# ESP32-H21 register map
Vendor: ESPRESSIF SYSTEMS (SHANGHAI) CO., LTD.; Series: ESP32 H-Series; File version: 1
CPU: RV32IMAC r0p0, little endian, no MPU, no FPU, 0 interrupt priority bits
Address unit: 32 bits
Registers are 32-bit, read-write, reset 0x0 unless marked. A register's access mark holds for its fields unless they carry their own. Offsets are from the block's base; [hi:lo] are bit positions; {n}, {i} and the like mark numbered series.

## DMA — DMA (Direct Memory Access) Controller
Base 0x60080000
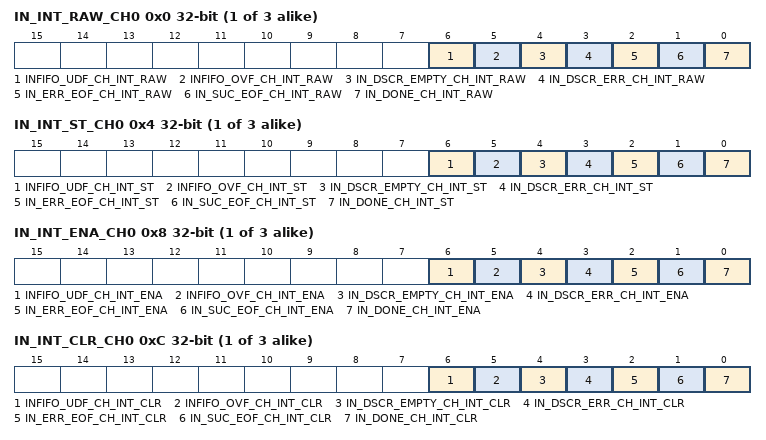
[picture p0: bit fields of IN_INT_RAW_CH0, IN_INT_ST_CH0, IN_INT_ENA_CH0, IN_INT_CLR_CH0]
{0x0+0x10*i} IN_INT_RAW_CH{i} (i=0..2) — Raw status interrupt of channel {i}
  [6] INFIFO_UDF_CH_INT_RAW — This raw interrupt bit turns to high level when level 1 fifo of Rx channel 0 is underflow.
  [5] INFIFO_OVF_CH_INT_RAW — This raw interrupt bit turns to high level when level 1 fifo of Rx channel 0 is overflow.
  [4] IN_DSCR_EMPTY_CH_INT_RAW — The raw interrupt bit turns to high level when Rx buffer pointed by inlink is full and receiving data is not completed but there is no more inlink for Rx channel 0.
  [3] IN_DSCR_ERR_CH_INT_RAW — The raw interrupt bit turns to high level when detecting inlink descriptor error including owner error and the second and third word error of inlink descriptor for Rx channel 0.
  [2] IN_ERR_EOF_CH_INT_RAW — The raw interrupt bit turns to high level when data error is detected only in the case that the peripheral is UHCI0 for Rx channel 0. For other peripherals this raw interrupt is reserved.
  [1] IN_SUC_EOF_CH_INT_RAW — The raw interrupt bit turns to high level when the last data pointed by one inlink descriptor has been received for Rx channel 0. For UHCI0 the raw interrupt bit turns to high level when the last data pointed by one inlink descriptor has been received and no data error is detected for Rx channel 0.
  [0] IN_DONE_CH_INT_RAW — The raw interrupt bit turns to high level when the last data pointed by one inlink descriptor has been received for Rx channel 0.
{0x4+0x10*i} IN_INT_ST_CH{i} (i=0..2) ro — Masked interrupt of channel {i}
  [6] INFIFO_UDF_CH_INT_ST — The raw interrupt status bit for the INFIFO_UDF_L1_CH_INT interrupt.
  [5] INFIFO_OVF_CH_INT_ST — The raw interrupt status bit for the INFIFO_OVF_L1_CH_INT interrupt.
  [4] IN_DSCR_EMPTY_CH_INT_ST — The raw interrupt status bit for the IN_DSCR_EMPTY_CH_INT interrupt.
  [3] IN_DSCR_ERR_CH_INT_ST — The raw interrupt status bit for the IN_DSCR_ERR_CH_INT interrupt.
  [2] IN_ERR_EOF_CH_INT_ST — The raw interrupt status bit for the IN_ERR_EOF_CH_INT interrupt.
  [1] IN_SUC_EOF_CH_INT_ST — The raw interrupt status bit for the IN_SUC_EOF_CH_INT interrupt.
  [0] IN_DONE_CH_INT_ST — The raw interrupt status bit for the IN_DONE_CH_INT interrupt.
{0x8+0x10*i} IN_INT_ENA_CH{i} (i=0..2) — Interrupt enable bits of channel {i}
  [6] INFIFO_UDF_CH_INT_ENA — The interrupt enable bit for the INFIFO_UDF_L1_CH_INT interrupt.
  [5] INFIFO_OVF_CH_INT_ENA — The interrupt enable bit for the INFIFO_OVF_L1_CH_INT interrupt.
  [4] IN_DSCR_EMPTY_CH_INT_ENA — The interrupt enable bit for the IN_DSCR_EMPTY_CH_INT interrupt.
  [3] IN_DSCR_ERR_CH_INT_ENA — The interrupt enable bit for the IN_DSCR_ERR_CH_INT interrupt.
  [2] IN_ERR_EOF_CH_INT_ENA — The interrupt enable bit for the IN_ERR_EOF_CH_INT interrupt.
  [1] IN_SUC_EOF_CH_INT_ENA — The interrupt enable bit for the IN_SUC_EOF_CH_INT interrupt.
  [0] IN_DONE_CH_INT_ENA — The interrupt enable bit for the IN_DONE_CH_INT interrupt.
{0xC+0x10*i} IN_INT_CLR_CH{i} (i=0..2) wo — Interrupt clear bits of channel {i}
  [6] INFIFO_UDF_CH_INT_CLR — Set this bit to clear the INFIFO_UDF_L1_CH_INT interrupt.
  [5] INFIFO_OVF_CH_INT_CLR — Set this bit to clear the INFIFO_OVF_L1_CH_INT interrupt.
  [4] IN_DSCR_EMPTY_CH_INT_CLR — Set this bit to clear the IN_DSCR_EMPTY_CH_INT interrupt.
  [3] IN_DSCR_ERR_CH_INT_CLR — Set this bit to clear the IN_DSCR_ERR_CH_INT interrupt.
  [2] IN_ERR_EOF_CH_INT_CLR — Set this bit to clear the IN_ERR_EOF_CH_INT interrupt.
  [1] IN_SUC_EOF_CH_INT_CLR — Set this bit to clear the IN_SUC_EOF_CH_INT interrupt.
  [0] IN_DONE_CH_INT_CLR — Set this bit to clear the IN_DONE_CH_INT interrupt.
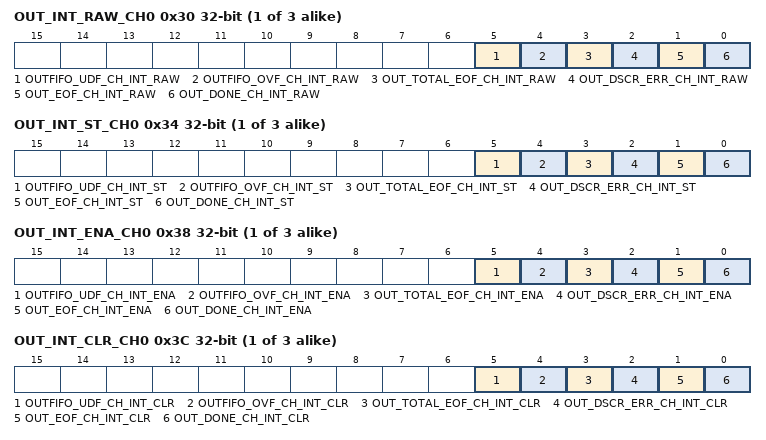
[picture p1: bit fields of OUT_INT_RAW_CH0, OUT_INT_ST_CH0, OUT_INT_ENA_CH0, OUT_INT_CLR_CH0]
{0x30+0x10*i} OUT_INT_RAW_CH{i} (i=0..2) — Raw status interrupt of channel {i}
  [5] OUTFIFO_UDF_CH_INT_RAW — This raw interrupt bit turns to high level when level 1 fifo of Tx channel 0 is underflow.
  [4] OUTFIFO_OVF_CH_INT_RAW — This raw interrupt bit turns to high level when level 1 fifo of Tx channel 0 is overflow.
  [3] OUT_TOTAL_EOF_CH_INT_RAW — The raw interrupt bit turns to high level when data corresponding a outlink (includes one link descriptor or few link descriptors) is transmitted out for Tx channel 0.
  [2] OUT_DSCR_ERR_CH_INT_RAW — The raw interrupt bit turns to high level when detecting outlink descriptor error including owner error and the second and third word error of outlink descriptor for Tx channel 0.
  [1] OUT_EOF_CH_INT_RAW — The raw interrupt bit turns to high level when the last data pointed by one outlink descriptor has been read from memory for Tx channel 0.
  [0] OUT_DONE_CH_INT_RAW — The raw interrupt bit turns to high level when the last data pointed by one outlink descriptor has been transmitted to peripherals for Tx channel 0.
{0x34+0x10*i} OUT_INT_ST_CH{i} (i=0..2) ro — Masked interrupt of channel {i}
  [5] OUTFIFO_UDF_CH_INT_ST — The raw interrupt status bit for the OUTFIFO_UDF_L1_CH_INT interrupt.
  [4] OUTFIFO_OVF_CH_INT_ST — The raw interrupt status bit for the OUTFIFO_OVF_L1_CH_INT interrupt.
  [3] OUT_TOTAL_EOF_CH_INT_ST — The raw interrupt status bit for the OUT_TOTAL_EOF_CH_INT interrupt.
  [2] OUT_DSCR_ERR_CH_INT_ST — The raw interrupt status bit for the OUT_DSCR_ERR_CH_INT interrupt.
  [1] OUT_EOF_CH_INT_ST — The raw interrupt status bit for the OUT_EOF_CH_INT interrupt.
  [0] OUT_DONE_CH_INT_ST — The raw interrupt status bit for the OUT_DONE_CH_INT interrupt.
{0x38+0x10*i} OUT_INT_ENA_CH{i} (i=0..2) — Interrupt enable bits of channel {i}
  [5] OUTFIFO_UDF_CH_INT_ENA — The interrupt enable bit for the OUTFIFO_UDF_L1_CH_INT interrupt.
  [4] OUTFIFO_OVF_CH_INT_ENA — The interrupt enable bit for the OUTFIFO_OVF_L1_CH_INT interrupt.
  [3] OUT_TOTAL_EOF_CH_INT_ENA — The interrupt enable bit for the OUT_TOTAL_EOF_CH_INT interrupt.
  [2] OUT_DSCR_ERR_CH_INT_ENA — The interrupt enable bit for the OUT_DSCR_ERR_CH_INT interrupt.
  [1] OUT_EOF_CH_INT_ENA — The interrupt enable bit for the OUT_EOF_CH_INT interrupt.
  [0] OUT_DONE_CH_INT_ENA — The interrupt enable bit for the OUT_DONE_CH_INT interrupt.
{0x3C+0x10*i} OUT_INT_CLR_CH{i} (i=0..2) wo — Interrupt clear bits of channel {i}
  [5] OUTFIFO_UDF_CH_INT_CLR — Set this bit to clear the OUTFIFO_UDF_L1_CH_INT interrupt.
  [4] OUTFIFO_OVF_CH_INT_CLR — Set this bit to clear the OUTFIFO_OVF_L1_CH_INT interrupt.
  [3] OUT_TOTAL_EOF_CH_INT_CLR — Set this bit to clear the OUT_TOTAL_EOF_CH_INT interrupt.
  [2] OUT_DSCR_ERR_CH_INT_CLR — Set this bit to clear the OUT_DSCR_ERR_CH_INT interrupt.
  [1] OUT_EOF_CH_INT_CLR — Set this bit to clear the OUT_EOF_CH_INT interrupt.
  [0] OUT_DONE_CH_INT_CLR — Set this bit to clear the OUT_DONE_CH_INT interrupt.
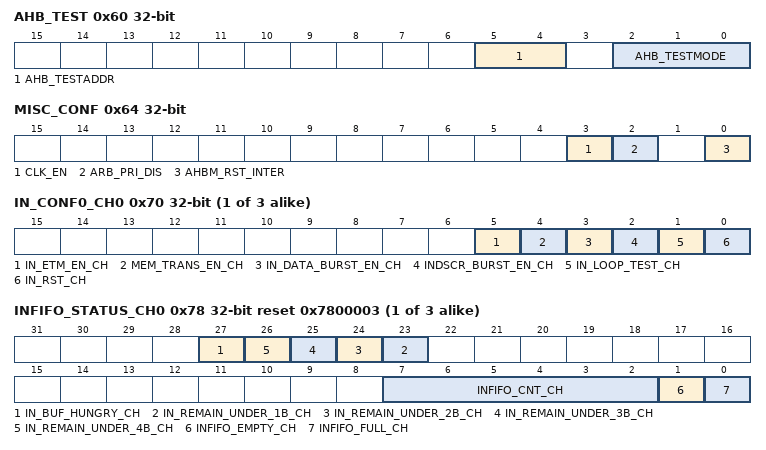
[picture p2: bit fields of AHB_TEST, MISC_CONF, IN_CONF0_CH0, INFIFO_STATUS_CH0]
0x60 AHB_TEST — reserved
  [5:4] AHB_TESTADDR — reserved
  [2:0] AHB_TESTMODE — reserved
0x64 MISC_CONF — MISC register
  [3] CLK_EN — 1'h1: Force clock on for register. 1'h0: Support clock only when application writes registers.
  [2] ARB_PRI_DIS — Set this bit to disable priority arbitration function.
  [0] AHBM_RST_INTER — Set this bit then clear this bit to reset the internal ahb FSM.
0x68 DATE reset 0x2202250 — Version control register
  [31:0] DATE — register version.
{0x70+0xC0*i} IN_CONF0_CH{i} (i=0..2) — Configure 0 register of Rx channel {i}
  [5] IN_ETM_EN_CH — Set this bit to 1 to enable etm control mode, dma Rx channel 0 is triggered by etm task.
  [4] MEM_TRANS_EN_CH — Set this bit 1 to enable automatic transmitting data from memory to memory via DMA.
  [3] IN_DATA_BURST_EN_CH — Set this bit to 1 to enable INCR burst transfer for Rx channel 0 receiving data when accessing internal SRAM.
  [2] INDSCR_BURST_EN_CH — Set this bit to 1 to enable INCR burst transfer for Rx channel 0 reading link descriptor when accessing internal SRAM.
  [1] IN_LOOP_TEST_CH — reserved
  [0] IN_RST_CH — This bit is used to reset DMA channel 0 Rx FSM and Rx FIFO pointer.
{0x74+0xC0*i} IN_CONF1_CH{i} (i=0..2) — Configure 1 register of Rx channel {i}
  [12] IN_CHECK_OWNER_CH — Set this bit to enable checking the owner attribute of the link descriptor.
{0x78+0xC0*i} INFIFO_STATUS_CH{i} (i=0..2) ro reset 0x7800003 — Receive FIFO status of Rx channel {i}
  [27] IN_BUF_HUNGRY_CH — reserved
  [n+22] IN_REMAIN_UNDER_{n}B_CH (n=1..4) — reserved
  [7:2] INFIFO_CNT_CH — The register stores the byte number of the data in L1 Rx FIFO for Rx channel 0.
  [1] INFIFO_EMPTY_CH — L1 Rx FIFO empty signal for Rx channel 0.
  [0] INFIFO_FULL_CH — L1 Rx FIFO full signal for Rx channel 0.
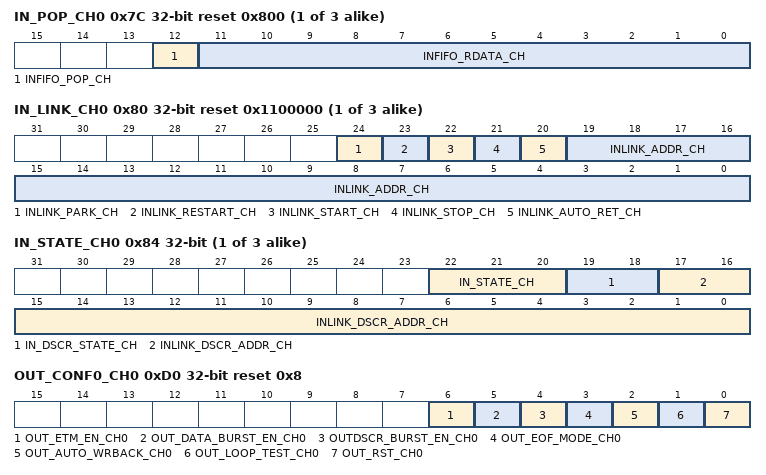
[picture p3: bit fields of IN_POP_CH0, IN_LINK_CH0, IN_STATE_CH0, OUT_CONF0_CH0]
{0x7C+0xC0*i} IN_POP_CH{i} (i=0..2) access per field reset 0x800 — Pop control register of Rx channel {i}
  [12] INFIFO_POP_CH wo — Set this bit to pop data from DMA FIFO.
  [11:0] INFIFO_RDATA_CH ro — This register stores the data popping from DMA FIFO.
{0x80+0xC0*i} IN_LINK_CH{i} (i=0..2) access per field reset 0x1100000 — Link descriptor configure and control register of Rx channel {i}
  [24] INLINK_PARK_CH ro — 1: the inlink descriptor's FSM is in idle state. 0: the inlink descriptor's FSM is working.
  [23] INLINK_RESTART_CH wo — Set this bit to mount a new inlink descriptor.
  [22] INLINK_START_CH wo — Set this bit to start dealing with the inlink descriptors.
  [21] INLINK_STOP_CH wo — Set this bit to stop dealing with the inlink descriptors.
  [20] INLINK_AUTO_RET_CH rw — Set this bit to return to current inlink descriptor's address when there are some errors in current receiving data.
  [19:0] INLINK_ADDR_CH rw — This register stores the 20 least significant bits of the first inlink descriptor's address.
{0x84+0xC0*i} IN_STATE_CH{i} (i=0..2) ro — Receive status of Rx channel {i}
  [22:20] IN_STATE_CH — reserved
  [19:18] IN_DSCR_STATE_CH — reserved
  [17:0] INLINK_DSCR_ADDR_CH — This register stores the current inlink descriptor's address.
{0x88+0xC0*i} IN_SUC_EOF_DES_ADDR_CH{i} (i=0..2) ro — Inlink descriptor address when EOF occurs of Rx channel {i}
  [31:0] IN_SUC_EOF_DES_ADDR_CH — This register stores the address of the inlink descriptor when the EOF bit in this descriptor is 1.
{0x8C+0xC0*i} IN_ERR_EOF_DES_ADDR_CH{i} (i=0..2) ro — Inlink descriptor address when errors occur of Rx channel {i}
  [31:0] IN_ERR_EOF_DES_ADDR_CH — This register stores the address of the inlink descriptor when there are some errors in current receiving data. Only used when peripheral is UHCI0.
{0x90+0xC0*i} IN_DSCR_CH{i} (i=0..2) ro — Current inlink descriptor address of Rx channel {i}
  [31:0] INLINK_DSCR_CH — The address of the current inlink descriptor x.
{0x94+0xC0*i} IN_DSCR_BF0_CH{i} (i=0..2) ro — The last inlink descriptor address of Rx channel {i}
  [31:0] INLINK_DSCR_BF0_CH — The address of the last inlink descriptor x-1.
{0x98+0xC0*i} IN_DSCR_BF1_CH{i} (i=0..2) ro — The second-to-last inlink descriptor address of Rx channel {i}
  [31:0] INLINK_DSCR_BF1_CH — The address of the second-to-last inlink descriptor x-2.
{0x9C+0xC0*i} IN_PRI_CH{i} (i=0..2) — Priority register of Rx channel {i}
  [3:0] RX_PRI_CH — The priority of Rx channel 0. The larger of the value the higher of the priority.
{0xA0+0xC0*i} IN_PERI_SEL_CH{i} (i=0..2) reset 0x3F — Peripheral selection of Rx channel {i}
  [5:0] PERI_IN_SEL_CH — This register is used to select peripheral for Rx channel 0. 0:SPI2. 1: Dummy. 2: UHCI0. 3: I2S0. 4: Dummy. 5: Dummy. 6: AES. 7: SHA. 8: ADC_DAC. 9: Parallel_IO. 10~15: Dummy
0xD0 OUT_CONF0_CH0 reset 0x8 — Configure 0 register of Tx channel 0
  [6] OUT_ETM_EN_CH0 — Set this bit to 1 to enable etm control mode, dma Tx channel 0 is triggered by etm task.
  [5] OUT_DATA_BURST_EN_CH0 — Set this bit to 1 to enable INCR burst transfer for Tx channel 0 transmitting data when accessing internal SRAM.
  [4] OUTDSCR_BURST_EN_CH0 — Set this bit to 1 to enable INCR burst transfer for Tx channel 0 reading link descriptor when accessing internal SRAM.
  [3] OUT_EOF_MODE_CH0 — EOF flag generation mode when transmitting data. 1: EOF flag for Tx channel 0 is generated when data need to transmit has been popped from FIFO in DMA
  [2] OUT_AUTO_WRBACK_CH0 — Set this bit to enable automatic outlink-writeback when all the data in tx buffer has been transmitted.
  [1] OUT_LOOP_TEST_CH0 — reserved
  [0] OUT_RST_CH0 — This bit is used to reset DMA channel 0 Tx FSM and Tx FIFO pointer.
{0xD4+0xC0*i} OUT_CONF1_CH{i} (i=0..2) — Configure 1 register of Tx channel {i}
  [12] OUT_CHECK_OWNER_CH — Set this bit to enable checking the owner attribute of the link descriptor.
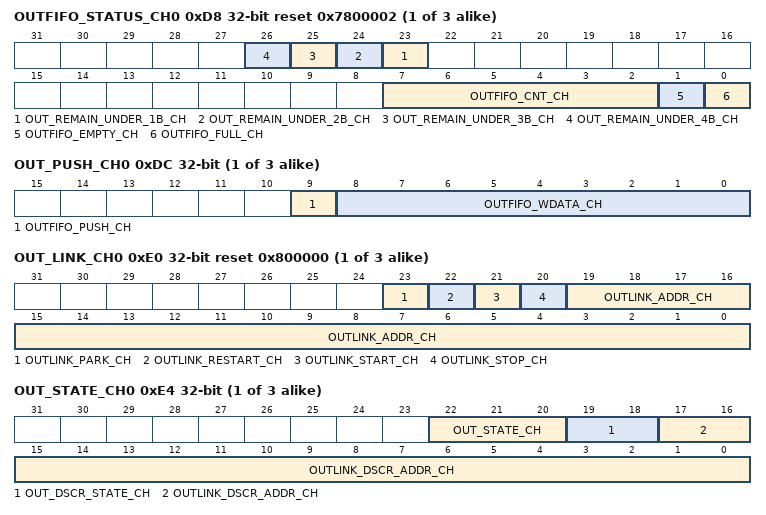
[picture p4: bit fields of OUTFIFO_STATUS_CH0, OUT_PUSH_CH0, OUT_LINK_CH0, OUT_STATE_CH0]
{0xD8+0xC0*i} OUTFIFO_STATUS_CH{i} (i=0..2) ro reset 0x7800002 — Transmit FIFO status of Tx channel {i}
  [n+22] OUT_REMAIN_UNDER_{n}B_CH (n=1..4) — reserved
  [7:2] OUTFIFO_CNT_CH — The register stores the byte number of the data in L1 Tx FIFO for Tx channel 0.
  [1] OUTFIFO_EMPTY_CH — L1 Tx FIFO empty signal for Tx channel 0.
  [0] OUTFIFO_FULL_CH — L1 Tx FIFO full signal for Tx channel 0.
{0xDC+0xC0*i} OUT_PUSH_CH{i} (i=0..2) access per field — Push control register of Rx channel {i}
  [9] OUTFIFO_PUSH_CH wo — Set this bit to push data into DMA FIFO.
  [8:0] OUTFIFO_WDATA_CH rw — This register stores the data that need to be pushed into DMA FIFO.
{0xE0+0xC0*i} OUT_LINK_CH{i} (i=0..2) access per field reset 0x800000 — Link descriptor configure and control register of Tx channel {i}
  [23] OUTLINK_PARK_CH ro — 1: the outlink descriptor's FSM is in idle state. 0: the outlink descriptor's FSM is working.
  [22] OUTLINK_RESTART_CH wo — Set this bit to restart a new outlink from the last address.
  [21] OUTLINK_START_CH wo — Set this bit to start dealing with the outlink descriptors.
  [20] OUTLINK_STOP_CH wo — Set this bit to stop dealing with the outlink descriptors.
  [19:0] OUTLINK_ADDR_CH rw — This register stores the 20 least significant bits of the first outlink descriptor's address.
{0xE4+0xC0*i} OUT_STATE_CH{i} (i=0..2) ro — Transmit status of Tx channel {i}
  [22:20] OUT_STATE_CH — reserved
  [19:18] OUT_DSCR_STATE_CH — reserved
  [17:0] OUTLINK_DSCR_ADDR_CH — This register stores the current outlink descriptor's address.
{0xE8+0xC0*i} OUT_EOF_DES_ADDR_CH{i} (i=0..2) ro — Outlink descriptor address when EOF occurs of Tx channel {i}
  [31:0] OUT_EOF_DES_ADDR_CH — This register stores the address of the outlink descriptor when the EOF bit in this descriptor is 1.
{0xEC+0xC0*i} OUT_EOF_BFR_DES_ADDR_CH{i} (i=0..2) ro — The last outlink descriptor address when EOF occurs of Tx channel {i}
  [31:0] OUT_EOF_BFR_DES_ADDR_CH — This register stores the address of the outlink descriptor before the last outlink descriptor.
{0xF0+0xC0*i} OUT_DSCR_CH{i} (i=0..2) ro — Current inlink descriptor address of Tx channel {i}
  [31:0] OUTLINK_DSCR_CH — The address of the current outlink descriptor y.
{0xF4+0xC0*i} OUT_DSCR_BF0_CH{i} (i=0..2) ro — The last inlink descriptor address of Tx channel {i}
  [31:0] OUTLINK_DSCR_BF0_CH — The address of the last outlink descriptor y-1.
{0xF8+0xC0*i} OUT_DSCR_BF1_CH{i} (i=0..2) ro — The second-to-last inlink descriptor address of Tx channel {i}
  [31:0] OUTLINK_DSCR_BF1_CH — The address of the second-to-last inlink descriptor x-2.
0xFC OUT_PRI_CH0 — Priority register of Tx channel 0.
  [3:0] TX_PRI_CH0 — The priority of Tx channel 0. The larger of the value the higher of the priority.
{0x100+0xC0*i} OUT_PERI_SEL_CH{i} (i=0..2) reset 0x3F — Peripheral selection of Tx channel {i}
  [5:0] PERI_OUT_SEL_CH — This register is used to select peripheral for Tx channel 0. 0:SPI2. 1: Dummy. 2: UHCI0. 3: I2S0. 4: Dummy. 5: Dummy. 6: AES. 7: SHA. 8: ADC_DAC. 9: Parallel_IO. 10~15: Dummy
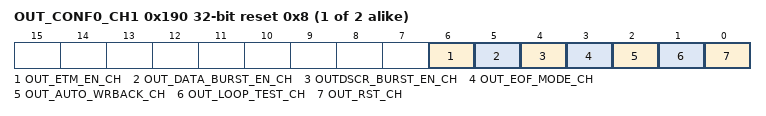
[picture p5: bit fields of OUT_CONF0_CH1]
{0xD0+0xC0*i} OUT_CONF0_CH{i} (i=1..2) reset 0x8 — Configure 0 register of Tx channel {i}
  [6] OUT_ETM_EN_CH — Set this bit to 1 to enable etm control mode, dma Tx channel 1 is triggered by etm task.
  [5] OUT_DATA_BURST_EN_CH — Set this bit to 1 to enable INCR burst transfer for Tx channel 1 transmitting data when accessing internal SRAM.
  [4] OUTDSCR_BURST_EN_CH — Set this bit to 1 to enable INCR burst transfer for Tx channel 1 reading link descriptor when accessing internal SRAM.
  [3] OUT_EOF_MODE_CH — EOF flag generation mode when transmitting data. 1: EOF flag for Tx channel 1 is generated when data need to transmit has been popped from FIFO in DMA
  [2] OUT_AUTO_WRBACK_CH — Set this bit to enable automatic outlink-writeback when all the data in tx buffer has been transmitted.
  [1] OUT_LOOP_TEST_CH — reserved
  [0] OUT_RST_CH — This bit is used to reset DMA channel 1 Tx FSM and Tx FIFO pointer.
0x1BC OUT_PRI_CH1 — Priority register of Tx channel 1
  [3:0] TX_PRI_CH1 — The priority of Tx channel 1. The larger of the value the higher of the priority.
0x27C OUT_PRI_CH2 — Priority register of Tx channel 2
  [3:0] TX_PRI_CH2 — The priority of Tx channel 2. The larger of the value the higher of the priority.
